# ESP32-C3 register map
Vendor: ESPRESSIF SYSTEMS (SHANGHAI) CO., LTD.; Series: ESP32 C-Series; File version: 19
CPU: RV32IMC r0p0, little endian, no MPU, no FPU, 0 interrupt priority bits
Address unit: 32 bits
Registers are 32-bit, read-write, reset 0x0 unless marked. A register's access mark holds for its fields unless they carry their own. Offsets are from the block's base; [hi:lo] are bit positions; {n}, {i} and the like mark numbered series.

## TIMG0 — Timer Group 0
Base 0x6001F000
Same registers: TIMG1 0x60020000
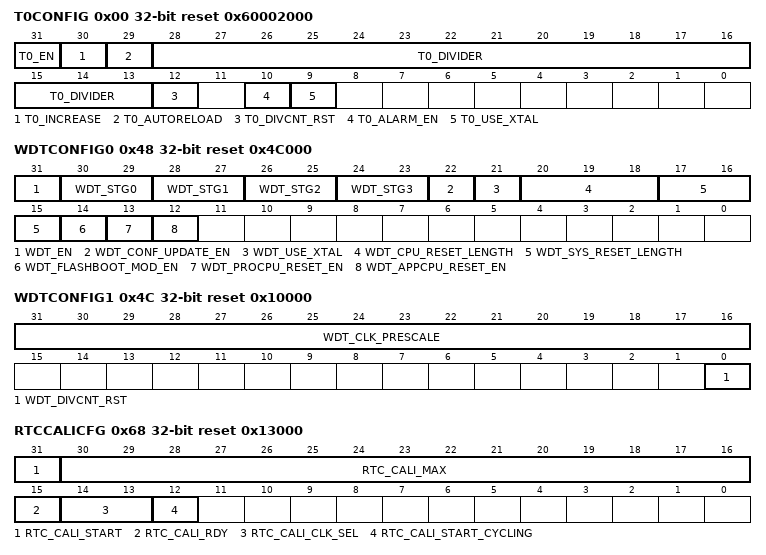
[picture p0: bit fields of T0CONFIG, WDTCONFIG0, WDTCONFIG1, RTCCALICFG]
0x00 T0CONFIG access per field reset 0x60002000 — TIMG_T0CONFIG_REG.
  [31] T0_EN rw — reg_t0_en.
  [30] T0_INCREASE rw — reg_t0_increase.
  [29] T0_AUTORELOAD rw — reg_t0_autoreload.
  [28:13] T0_DIVIDER rw — reg_t0_divider.
  [12] T0_DIVCNT_RST wo — reg_t0_divcnt_rst.
  [10] T0_ALARM_EN rw — reg_t0_alarm_en.
  [9] T0_USE_XTAL rw — reg_t0_use_xtal.
0x04 T0LO ro — TIMG_T0LO_REG.
  [31:0] T0_LO
0x08 T0HI ro — TIMG_T0HI_REG.
  [21:0] T0_HI
0x0C T0UPDATE — TIMG_T0UPDATE_REG.
  [31] T0_UPDATE
0x10 T0ALARMLO — TIMG_T0ALARMLO_REG.
  [31:0] T0_ALARM_LO — reg_t0_alarm_lo.
0x14 T0ALARMHI — TIMG_T0ALARMHI_REG.
  [21:0] T0_ALARM_HI — reg_t0_alarm_hi.
0x18 T0LOADLO — TIMG_T0LOADLO_REG.
  [31:0] T0_LOAD_LO — reg_t0_load_lo.
0x1C T0LOADHI — TIMG_T0LOADHI_REG.
  [21:0] T0_LOAD_HI — reg_t0_load_hi.
0x20 T0LOAD wo — TIMG_T0LOAD_REG.
  [31:0] T0_LOAD
0x48 WDTCONFIG0 access per field reset 0x4C000 — TIMG_WDTCONFIG0_REG.
  [31] WDT_EN rw — reg_wdt_en.
  [30-2n:29-2n] WDT_STG{n} rw (n=0..3) — reg_wdt_stg{n}.
  [22] WDT_CONF_UPDATE_EN wo — reg_wdt_conf_update_en.
  [21] WDT_USE_XTAL rw — reg_wdt_use_xtal.
  [20:18] WDT_CPU_RESET_LENGTH rw — reg_wdt_cpu_reset_length.
  [17:15] WDT_SYS_RESET_LENGTH rw — reg_wdt_sys_reset_length.
  [14] WDT_FLASHBOOT_MOD_EN rw — reg_wdt_flashboot_mod_en.
  [13] WDT_PROCPU_RESET_EN rw — reg_wdt_procpu_reset_en.
  [12] WDT_APPCPU_RESET_EN rw — reg_wdt_appcpu_reset_en.
0x4C WDTCONFIG1 access per field reset 0x10000 — TIMG_WDTCONFIG1_REG.
  [31:16] WDT_CLK_PRESCALE rw — reg_wdt_clk_prescale.
  [0] WDT_DIVCNT_RST wo — reg_wdt_divcnt_rst.
0x50 WDTCONFIG2 reset 0x18CBA80 — TIMG_WDTCONFIG2_REG.
  [31:0] WDT_STG0_HOLD — reg_wdt_stg0_hold.
0x54 WDTCONFIG3 reset 0x7FFFFFF — TIMG_WDTCONFIG3_REG.
  [31:0] WDT_STG1_HOLD — reg_wdt_stg1_hold.
0x58 WDTCONFIG4 reset 0xFFFFF — TIMG_WDTCONFIG4_REG.
  [31:0] WDT_STG2_HOLD — reg_wdt_stg2_hold.
0x5C WDTCONFIG5 reset 0xFFFFF — TIMG_WDTCONFIG5_REG.
  [31:0] WDT_STG3_HOLD — reg_wdt_stg3_hold.
0x60 WDTFEED wo — TIMG_WDTFEED_REG.
  [31:0] WDT_FEED
0x64 WDTWPROTECT reset 0x50D83AA1 — TIMG_WDTWPROTECT_REG.
  [31:0] WDT_WKEY — reg_wdt_wkey.
0x68 RTCCALICFG access per field reset 0x13000 — TIMG_RTCCALICFG_REG.
  [31] RTC_CALI_START rw — reg_rtc_cali_start.
  [30:16] RTC_CALI_MAX rw — reg_rtc_cali_max.
  [15] RTC_CALI_RDY ro
  [14:13] RTC_CALI_CLK_SEL rw — reg_rtc_cali_clk_sel.0:rtcslowclock.1:clk_80m.2:xtal_32k
  [12] RTC_CALI_START_CYCLING rw — reg_rtc_cali_start_cycling.
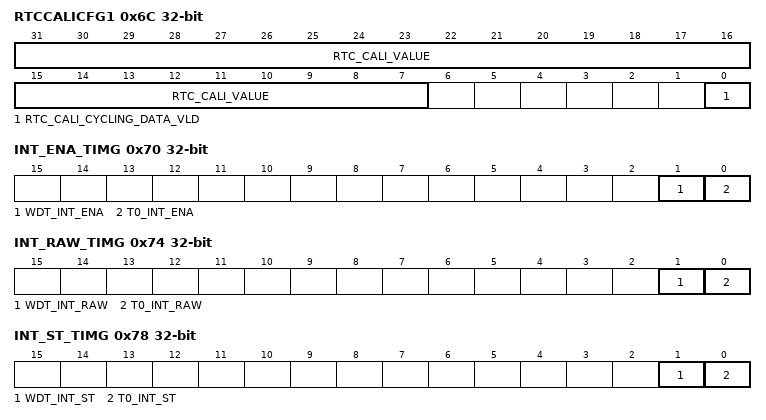
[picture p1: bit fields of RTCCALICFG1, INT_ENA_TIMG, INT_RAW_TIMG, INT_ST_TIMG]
0x6C RTCCALICFG1 ro — TIMG_RTCCALICFG1_REG.
  [31:7] RTC_CALI_VALUE, [0] RTC_CALI_CYCLING_DATA_VLD
0x70 INT_ENA_TIMG — INT_ENA_TIMG_REG
  [1] WDT_INT_ENA, [0] T0_INT_ENA
0x74 INT_RAW_TIMG ro — INT_RAW_TIMG_REG
  [1] WDT_INT_RAW, [0] T0_INT_RAW
0x78 INT_ST_TIMG ro — INT_ST_TIMG_REG
  [1] WDT_INT_ST, [0] T0_INT_ST
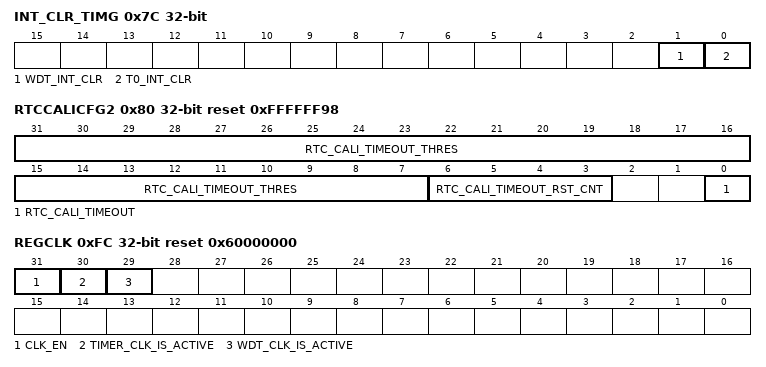
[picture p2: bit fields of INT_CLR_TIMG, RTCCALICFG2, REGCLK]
0x7C INT_CLR_TIMG wo — INT_CLR_TIMG_REG
  [1] WDT_INT_CLR, [0] T0_INT_CLR
0x80 RTCCALICFG2 access per field reset 0xFFFFFF98 — TIMG_RTCCALICFG2_REG.
  [31:7] RTC_CALI_TIMEOUT_THRES rw — reg_rtc_cali_timeout_thres.timeoutifcalivaluecountsoverthreshold
  [6:3] RTC_CALI_TIMEOUT_RST_CNT rw — reg_rtc_cali_timeout_rst_cnt.Cyclesthatreleasecalibrationtimeoutreset
  [0] RTC_CALI_TIMEOUT ro — timeoutindicator
0xF8 NTIMG_DATE reset 0x2006191 — TIMG_NTIMG_DATE_REG.
  [27:0] NTIMGS_DATE — reg_ntimers_date.
0xFC REGCLK reset 0x60000000 — TIMG_REGCLK_REG.
  [31] CLK_EN — reg_clk_en.
  [30] TIMER_CLK_IS_ACTIVE — reg_timer_clk_is_active.
  [29] WDT_CLK_IS_ACTIVE — reg_wdt_clk_is_active.

## XTS_AES — XTS-AES-128 Flash Encryption
Base 0x600CC000
{0x0+i} PLAIN_MEM[{i}] (i=0..15) 8-bit access not given — The memory that stores plaintext
0x40 LINESIZE — XTS-AES line-size register
  [0] LINESIZE — This bit stores the line size parameter. 0: 16Byte, 1: 32Byte.
0x44 DESTINATION — XTS-AES destination register
  [0] DESTINATION — This bit stores the destination. 0: flash(default). 1: reserved.
0x48 PHYSICAL_ADDRESS — XTS-AES physical address register
  [29:0] PHYSICAL_ADDRESS — Those bits stores the physical address. If linesize is 16-byte, the physical address should be aligned of 16 bytes. If linesize is 32-byte, the physical address should be aligned of 32 bytes.
0x4C TRIGGER wo — XTS-AES trigger register
  [0] TRIGGER — Set this bit to start manual encryption calculation
0x50 RELEASE wo — XTS-AES release register
  [0] RELEASE — Set this bit to release the manual encrypted result, after that the result will be visible to spi
0x54 DESTROY wo — XTS-AES destroy register
  [0] DESTROY — Set this bit to destroy XTS-AES result.
0x58 STATE ro — XTS-AES status register
  [1:0] STATE — Those bits shows XTS-AES status. 0=IDLE, 1=WORK, 2=RELEASE, 3=USE. IDLE means that XTS-AES is idle. WORK means that XTS-AES is busy with calculation. RELEASE means the encrypted result is generated but not visible to mspi. USE means that the encrypted result is visible to mspi.
0x5C DATE reset 0x20200623 — XTS-AES version control register
  [29:0] DATE — Those bits stores the version information of XTS-AES.
